# STM32L486xx register map
File version: 1.0
Registers are 32-bit, read-write, reset 0x0 unless marked. A register's access mark holds for its fields unless they carry their own. Offsets are from the block's base; [hi:lo] are bit positions; {n}, {i} and the like mark numbered series.

## TIM1 — TIM
Base 0x40012C00
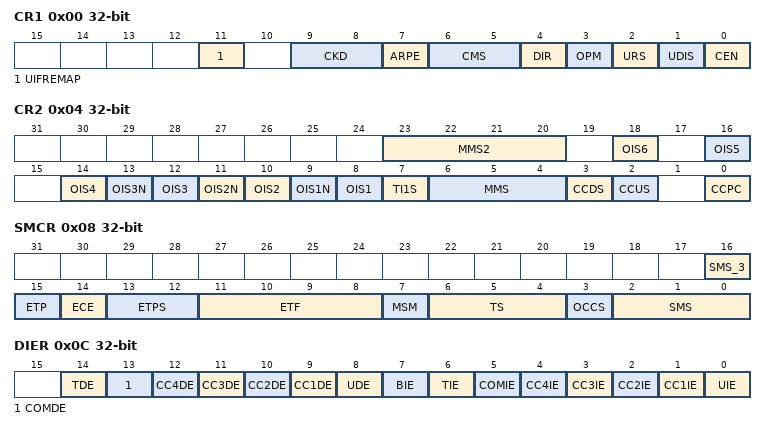
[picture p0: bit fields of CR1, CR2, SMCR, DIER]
0x00 CR1 — TIM control register 1
  [11] UIFREMAP — Update interrupt flag remap
  [9:8] CKD — CKD[1:0] bits (clock division)
    0=DIV1 (tDTS=tCK_INT); 1=DIV2 (tDTS=2*tCK_INT); 2=DIV4 (tDTS=4*tCK_INT)
  [7] ARPE — Auto-reload preload enable
  [6:5] CMS — CMS[1:0] bits (Center-aligned mode selection)
  [4] DIR — Direction
    0=UP (Timer counter counts up); 1=DOWN (Timer counter counts down)
  [3] OPM — One pulse mode
    1=SINGLE (Counter stops counting at the next update event); 0=REPETITIVE (Counter is not stopped at update event)
  [2] URS — Update request source
    0=REGULAR (Counter overflow/underflow, Setting the UG bit or Update generation through the slave mode controller generates an update request); 1=COUNTER (Only counter overflow/underflow generates an update request)
  [1] UDIS — Update disable
  [0] CEN — Counter enable
0x04 CR2 — TIM control register 2
  [23:20] MMS2 — MMS[2:0] bits (Master Mode Selection)
    0=RESET (UG bit from the TIMx_EGR register is used as trigger output 2); 1=ENABLE (Counter Enable signal (CNT_EN) is used as trigger output 2); 2=UPDATE (Update event is used as trigger output 2); 3=CC1F (CC1 capture or a compare match is used as trigger output 2); {v}=OC{v-3} (OC{v-3}REF signal is used as trigger output 2) (v=4..9); 10=OC4_RISINGFALLING (OC4REF rising or falling edges are used as trigger output 2); 11=OC6_RISINGFALLING (OC6REF rising or falling edges are used as trigger output 2); 12=OC4_RISING_OC6_RISING (OC4REF or OC6REF rising edges are used as trigger output 2); 13=OC4_RISING_OC6_FALLING (OC4REF rising or OC6REF falling edges are used as trigger output 2); 14=OC5_RISING_OC6_RISING (OC5REF or OC6REF rising edges are used as trigger output 2); 15=OC5_RISING_OC6_FALLING (OC5REF rising or OC6REF falling edges are used as trigger output 2)
  [2n+6] OIS{n} (n=1..6) — Output Idle state {n} (OC{n} output)
  [13] OIS3N — Output Idle state 3 (OC3N output)
  [11] OIS2N — Output Idle state 2 (OC2N output)
  [9] OIS1N — Output Idle state 1 (OC1N output)
  [7] TI1S — TI1 Selection
  [6:4] MMS — MMS[2:0] bits (Master Mode Selection)
    0=RESET (UG bit from the TIMx_EGR register is used as trigger output); 1=ENABLE (Counter Enable signal (CNT_EN) is used as trigger output); 2=UPDATE (Update event is used as trigger output); 3=CC1IF (CC1 capture or a compare match is used as trigger output); {v}=OC{v-3}REF (OC{v-3}REF signal is used as trigger output) (v=4..7)
  [3] CCDS — Capture/Compare DMA Selection
    0=CC (CCx DMA request sent when CCx event occurs); 1=UPDATE (CCx DMA requests sent when update event occurs)
  [2] CCUS — Capture/Compare Control Update Selection
    0=ONLY (Capture/compare control bits are updated by setting the COMG bit only); 1=AND_TRGI (Capture/compare control bits are updated by setting the COMG bit or when a rising edge occurs on trigger input (TRGI))
  [0] CCPC — Capture/Compare Preloaded Control
0x08 SMCR — TIM slave mode control register
  [16] SMS_3 — SMS[2:0] bits (Slave mode selection)
  [15] ETP — External trigger polarity
  [14] ECE — External clock enable
  [13:12] ETPS — ETPS[1:0] bits (External trigger prescaler)
  [11:8] ETF — ETF[3:0] bits (External trigger filter)
  [7] MSM — Master/slave mode
  [6:4] TS — TS[2:0] bits (Trigger selection)
    {v}=ITR{v} (Internal Trigger {v} (ITR{v}) is used as trigger input) (v=0..3); 4=TI1F_ED (TI1 Edge Detector (TI1F_ED) is used as trigger input); 5=TI1FP1 (Filtered Timer Input 1 (TI1FP1) is used as trigger input); 6=TI2FP2 (Filtered Timer Input 2 (TI12P2) is used as trigger input); 7=ETRF (Filtered external Trigger (ETRF) is used as trigger input)
  [3] OCCS — OCREF clear selection
    0=NC (OCREF_CLR_INT is not connected); 1=ETR (OCREF_CLR_INT is connected to ETRF)
  [2:0] SMS — SMS[2:0] bits (Slave mode selection)
0x0C DIER — TIM DMA/interrupt enable register
  [14] TDE — Trigger DMA request enable
  [13] COMDE — COM DMA request enable
  [n+8] CC{n}DE (n=1..4) — Capture/Compare {n} DMA request enable
  [8] UDE — Update DMA request enable
  [7] BIE — Break interrupt enable
  [6] TIE — Trigger interrupt enable
  [5] COMIE — COM interrupt enable
  [n] CC{n}IE (n=1..4) — Capture/Compare {n} interrupt enable
  [0] UIE — Update interrupt enable
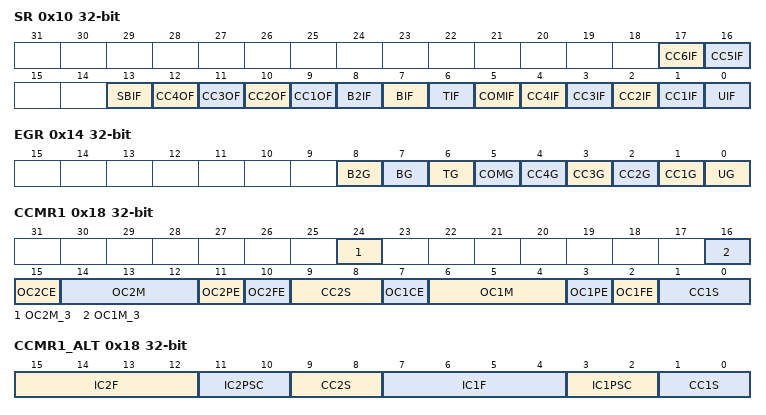
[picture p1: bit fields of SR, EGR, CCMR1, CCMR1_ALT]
0x10 SR — TIM status register
  [17] CC6IF — Capture/Compare 6 interrupt Flag
  [16] CC5IF — Capture/Compare 5 interrupt Flag
  [13] SBIF — System Break interrupt Flag
  [n+8] CC{n}OF (n=1..4) — Capture/Compare {n} Overcapture Flag
  [8] B2IF — Break 2 interrupt Flag
  [7] BIF — Break interrupt Flag
  [6] TIF — Trigger interrupt Flag
  [5] COMIF — COM interrupt Flag
  [n] CC{n}IF (n=1..4) — Capture/Compare {n} interrupt Flag
  [0] UIF — Update interrupt Flag
0x14 EGR — TIM event generation register
  [8] B2G — Break 2 Generation
  [7] BG — Break Generation
  [6] TG — Trigger Generation
  [5] COMG — Capture/Compare Control Update Generation
  [n] CC{n}G (n=1..4) — Capture/Compare {n} Generation
  [0] UG — Update Generation
0x18 CCMR1 — TIM capture/compare mode register 1
  [24] OC2M_3 — OC2M[2:0] bits (Output Compare 2 Mode)
  [16] OC1M_3 — OC1M[2:0] bits (Output Compare 1 Mode)
  [15] OC2CE — Output Compare 2 Clear Enable
  [14:12] OC2M — OC2M[2:0] bits (Output Compare 2 Mode)
  [11] OC2PE — Output Compare 2 Preload enable
  [10] OC2FE — Output Compare 2 Fast enable
  [9:8] CC2S — CC2S[1:0] bits (Capture/Compare 2 Selection)
  [7] OC1CE — Output Compare 1 Clear Enable
  [6:4] OC1M — OC1M[2:0] bits (Output Compare 1 Mode)
  [3] OC1PE — Output Compare 1 Preload enable
  [2] OC1FE — Output Compare 1 Fast enable
  [1:0] CC1S — CC1S[1:0] bits (Capture/Compare 1 Selection)
0x18 CCMR1_ALT (alternate view of CCMR1) — TIM capture/compare mode register 1
  [15:12] IC2F — IC2F[3:0] bits (Input Capture 2 Filter)
  [11:10] IC2PSC — IC2PSC[1:0] bits (Input Capture 2 Prescaler)
  [9:8] CC2S — CC2S[1:0] bits (Capture/Compare 2 Selection)
  [7:4] IC1F — IC1F[3:0] bits (Input Capture 1 Filter)
  [3:2] IC1PSC — IC1PSC[1:0] bits (Input Capture 1 Prescaler)
  [1:0] CC1S — CC1S[1:0] bits (Capture/Compare 1 Selection)
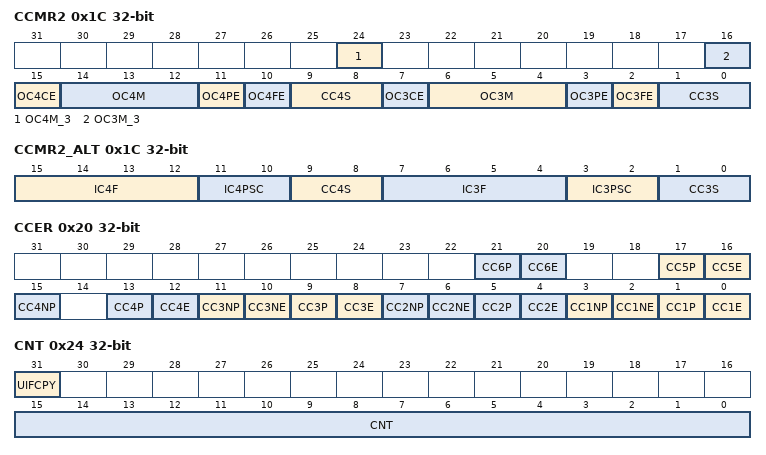
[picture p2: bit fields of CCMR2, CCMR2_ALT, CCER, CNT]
0x1C CCMR2 — TIM capture/compare mode register 2
  [24] OC4M_3 — OC4M[2:0] bits (Output Compare 4 Mode)
  [16] OC3M_3 — OC3M[2:0] bits (Output Compare 3 Mode)
  [15] OC4CE — Output Compare 4 Clear Enable
  [14:12] OC4M — OC4M[2:0] bits (Output Compare 4 Mode)
  [11] OC4PE — Output Compare 4 Preload enable
  [10] OC4FE — Output Compare 4 Fast enable
  [9:8] CC4S — CC4S[1:0] bits (Capture/Compare 4 Selection)
  [7] OC3CE — Output Compare 3 Clear Enable
  [6:4] OC3M — OC3M[2:0] bits (Output Compare 3 Mode)
  [3] OC3PE — Output Compare 3 Preload enable
  [2] OC3FE — Output Compare 3 Fast enable
  [1:0] CC3S — CC3S[1:0] bits (Capture/Compare 3 Selection)
0x1C CCMR2_ALT (alternate view of CCMR2) — TIM capture/compare mode register 2
  [15:12] IC4F — IC4F[3:0] bits (Input Capture 4 Filter)
  [11:10] IC4PSC — IC4PSC[1:0] bits (Input Capture 4 Prescaler)
  [9:8] CC4S — CC4S[1:0] bits (Capture/Compare 4 Selection)
  [7:4] IC3F — IC3F[3:0] bits (Input Capture 3 Filter)
  [3:2] IC3PSC — IC3PSC[1:0] bits (Input Capture 3 Prescaler)
  [1:0] CC3S — CC3S[1:0] bits (Capture/Compare 3 Selection)
0x20 CCER — TIM capture/compare enable register
  [4n-3] CC{n}P (n=1..6) — Capture/Compare {n} output Polarity
  [4n-4] CC{n}E (n=1..6) — Capture/Compare {n} output enable
  [4n-1] CC{n}NP (n=1..4) — Capture/Compare {n} Complementary output Polarity
  [10] CC3NE — Capture/Compare 3 Complementary output enable
  [6] CC2NE — Capture/Compare 2 Complementary output enable
  [2] CC1NE — Capture/Compare 1 Complementary output enable
0x24 CNT — TIM counter register
  [31] UIFCPY — Update interrupt flag copy (if UIFREMAP=1)
  [15:0] CNT — Counter Value
0x28 PSC — TIM prescaler
  [15:0] PSC — Prescaler Value
0x2C ARR — TIM auto-reload register
  [15:0] ARR — Actual auto-reload Value
0x30 RCR — TIM repetition counter register
  [15:0] REP — Repetition Counter Value
{0x30+4i} CCR{i} (i=1..4) — TIM capture/compare register {i}
  [15:0] CCR{i} — Capture/Compare {i} Value
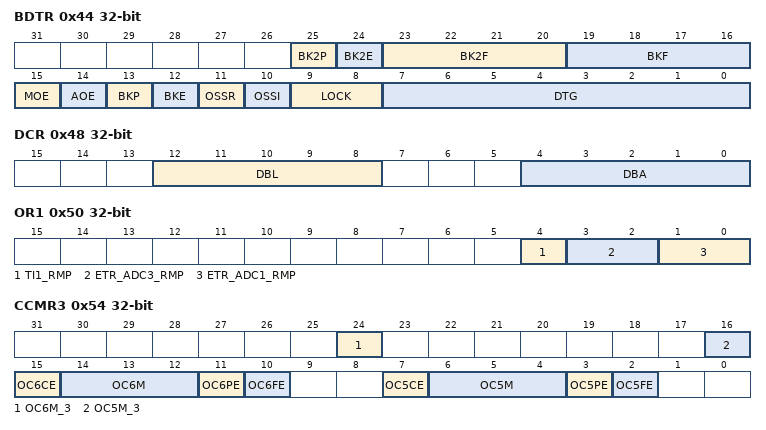
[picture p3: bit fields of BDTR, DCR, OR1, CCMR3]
0x44 BDTR — TIM break and dead-time register
  [25] BK2P — Break Polarity for Break 2
  [24] BK2E — Break enable for Break 2
  [23:20] BK2F — Break Filter for Break 2
  [19:16] BKF — Break Filter for Break 1
  [15] MOE — Main Output enable
  [14] AOE — Automatic Output enable
  [13] BKP — Break Polarity for Break 1
  [12] BKE — Break enable for Break 1
  [11] OSSR — Off-State Selection for Run mode
  [10] OSSI — Off-State Selection for Idle mode
  [9:8] LOCK — LOCK[1:0] bits (Lock Configuration)
    0=OFF (LOCK OFF - No bit is write protected); 1=LOCKLEVEL_1; 2=LOCKLEVEL_2; 3=LOCKLEVEL_3
  [7:0] DTG — DTG[0:7] bits (Dead-Time Generator set-up)
0x48 DCR — TIM DMA control register
  [12:8] DBL — DBL[4:0] bits (DMA Burst Length)
  [4:0] DBA — DBA[4:0] bits (DMA Base Address)
0x4C DMAR — TIM DMA address for full transfer
  [15:0] DMAB — DMA register for burst accesses
0x50 OR1 — TIM option register 1
  [4] TI1_RMP — TIM1 Input Capture 1 remap
  [3:2] ETR_ADC3_RMP — ETR_ADC3_RMP[1:0] bits (TIM1 ETR remap on ADC3)
  [1:0] ETR_ADC1_RMP — ETR_ADC1_RMP[1:0] bits (TIM1 ETR remap on ADC1)
0x54 CCMR3 — TIM capture/compare mode register 3
  [24] OC6M_3 — OC6M[3:0] bits (Output Compare 6 Mode)
  [16] OC5M_3 — OC5M[3:0] bits (Output Compare 5 Mode)
  [15] OC6CE — Output Compare 6 Clear Enable
  [14:12] OC6M — OC6M[3:0] bits (Output Compare 6 Mode)
  [11] OC6PE — Output Compare 6 Preload enable
  [10] OC6FE — Output Compare 6 Fast enable
  [7] OC5CE — Output Compare 5 Clear Enable
  [6:4] OC5M — OC5M[3:0] bits (Output Compare 5 Mode)
  [3] OC5PE — Output Compare 5 Preload enable
  [2] OC5FE — Output Compare 5 Fast enable
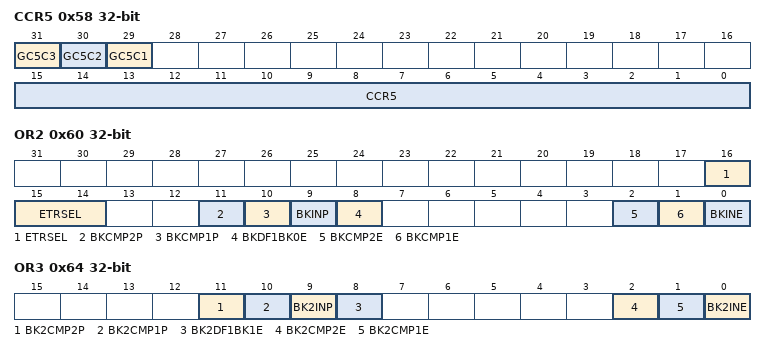
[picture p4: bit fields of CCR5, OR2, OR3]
0x58 CCR5 — TIM capture/compare register5
  [31] GC5C3 — Group Channel 5 and Channel 3
  [30] GC5C2 — Group Channel 5 and Channel 2
  [29] GC5C1 — Group Channel 5 and Channel 1
  [15:0] CCR5 — Capture/Compare 5 Value
0x5C CCR6 — TIM capture/compare register6
  [15:0] CCR6 — Capture/Compare 6 Value
0x60 OR2 — TIM option register 2
  [16:14] ETRSEL — ETRSEL[2:0] bits (TIM1 ETR source selection)
  [11] BKCMP2P — BRK COMP2 input polarity
  [10] BKCMP1P — BRK COMP1 input polarity
  [9] BKINP — BRK BKIN input polarity
  [8] BKDF1BK0E — BRK DFSDM1_BREAK[0] enable
  [2] BKCMP2E — BRK COMP2 enable
  [1] BKCMP1E — BRK COMP1 enable
  [0] BKINE — BRK BKIN input enable
0x64 OR3 — TIM option register 3
  [11] BK2CMP2P — BRK2 COMP2 input polarity
  [10] BK2CMP1P — BRK2 COMP1 input polarity
  [9] BK2INP — BRK2 BKIN2 input polarity
  [8] BK2DF1BK1E — BRK2 DFSDM1_BREAK[1] enable
  [2] BK2CMP2E — BRK2 COMP2 enable
  [1] BK2CMP1E — BRK2 COMP1 enable
  [0] BK2INE — BRK2 BKIN2 input enable

## TIM8 — TIM
Base 0x40013400
Registers as TIM1; these are added or differ:
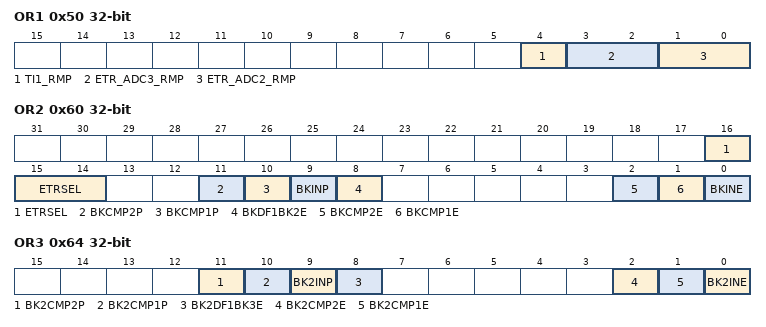
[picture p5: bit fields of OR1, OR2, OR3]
0x50 OR1 — TIM option register 1
  [4] TI1_RMP — TIM8 Input Capture 1 remap
  [3:2] ETR_ADC3_RMP — ETR_ADC3_RMP[1:0] bits (TIM8 ETR remap on ADC3)
  [1:0] ETR_ADC2_RMP — ETR_ADC2_RMP[1:0] bits (TIM8 ETR remap on ADC2)
0x60 OR2 — TIM option register 2
  [16:14] ETRSEL — ETRSEL[2:0] bits (TIM8 ETR source selection)
  [11] BKCMP2P — BRK COMP2 input polarity
  [10] BKCMP1P — BRK COMP1 input polarity
  [9] BKINP — BRK BKIN input polarity
  [8] BKDF1BK2E — BRK DFSDM1_BREAK[2] enable
  [2] BKCMP2E — BRK COMP2 enable
  [1] BKCMP1E — BRK COMP1 enable
  [0] BKINE — BRK BKIN input enable
0x64 OR3 — TIM option register 3
  [11] BK2CMP2P — BRK2 COMP2 input polarity
  [10] BK2CMP1P — BRK2 COMP1 input polarity
  [9] BK2INP — BRK2 BKIN2 input polarity
  [8] BK2DF1BK3E — BRK2 DFSDM1_BREAK[3] enable
  [2] BK2CMP2E — BRK2 COMP2 enable
  [1] BK2CMP1E — BRK2 COMP1 enable
  [0] BK2INE — BRK2 BKIN2 input enable
